# D1H.pdf register map
Vendor: Allwinner; Series: D1H.pdf; File version: 0.1
CPU: XuanTie C906 RISC-V CPU 0, little endian, MPU, FPU, double-precision FPU, 0 interrupt priority bits
Registers are 32-bit, read-write, reset 0x0 unless marked. A register's access mark holds for its fields unless they carry their own. Offsets are from the block's base; [hi:lo] are bit positions.

## CIR_TX
Base 0x02003000
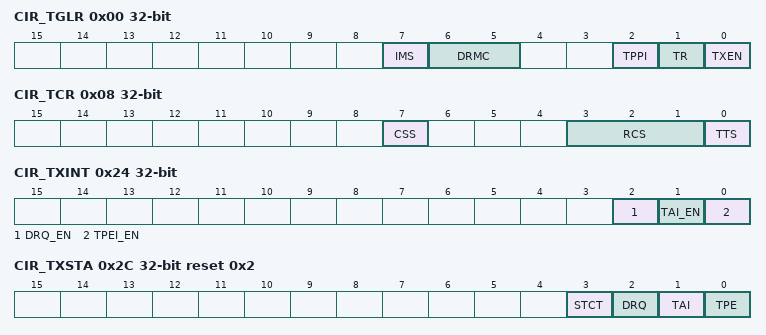
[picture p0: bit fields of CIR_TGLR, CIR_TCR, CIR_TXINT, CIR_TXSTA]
0x00 CIR_TGLR — CIR Transmit Global Register
  [7] IMS — Internal Modulation Select 0: The transmitting signal is not modulated 1: The transmitting signal is modulated internally
    0=not_modulated (The transmitting signal is not modulated); 1=modulated (The transmitting signal is modulated internally)
  [6:5] DRMC — Duty ratio of modulated carrier is high level/low level. 00: Low level is equal to high level 01: Low level is the double of high level 10: Low level is the triple of high level 11: Reserved
    0=equal (Low level is equal to high level); 1=the_double (Low level is the double of high level); 2=the_triple (Low level is the triple of high level)
  [2] TPPI — Transmit Pulse Polarity Invert 0: Not invert transmit pulse 1: Invert transmit pulse
    0=Not invert transmit pulse; 1=Invert transmit pulse
  [1] TR — Transmit Reset When this bit is set, the transmitting is reset. The FIFO will be flushed, the TIC filed and the CSS field will be cleared during Transmit Reset. This field will automatically be cleared when the Transmit Reset is finished, and the CIR transmitter will state Idle.
  [0] TXEN — Transmit Block Enable 0: Disable the CIR Transmitter 1: Enable the CIR Transmitter
    0=Disable the CIR Transmitter; 1=Enable the CIR Transmitter
0x04 CIR_TMCR reset 0x9E — CIR Transmit Modulation Control Register
  [7:0] RFMC — Reference Frequency of modulated carrier. Reference Frequency of modulated carrier based on a division of a fixed functional clock (FCLK). The range of the modulated carrier is usually 30 kHz to 60 kHz. Most consumer electronics is 38 kHz. The default modulated carrier is 38 kHz when FCLK is 12 MHz. RFMC= FCLK/((N+1)*(DRMC+2)).
0x08 CIR_TCR — CIR Transmit Control Register
  [7] CSS — Cyclical Pulse Start/Stop Control 0: Stop when cleared to '0'. From start to stop, all data in FIFO must be transmitted. 1: Start. Start to transmit when it is set to '1'.
    0=Stop when cleared to '0'. From start to stop, all data in FIFO must be transmitted.; 1=Start. Start to transmit when it is set to '1'.
  [3:1] RCS — Reference Clock Select for CIR Transmit The data in TX_FIFO is used to describe the pulse in Run-Length Code. The basic unit of pulse width is Reference Clock. 000: CIR Transmit reference clock is ir_clk 001: CIR Transmit reference clock is ir_clk/2 010: CIR Transmit reference clock is ir_clk/4 011: CIR Transmit reference clock is ir_clk/8 100: CIR Transmit reference clock is ir_clk/64 101: CIR Transmit reference clock is ir_clk/128 110: CIR Transmit reference clock is ir_clk/256 111: CIR Transmit reference clock is ir_clk/512
    0=ir_clk (CIR Transmit reference clock is ir_clk); 1=ir_clk_slash_2 (CIR Transmit reference clock is ir_clk/2); 2=ir_clk_slash_4 (CIR Transmit reference clock is ir_clk/4); 3=ir_clk_slash_8 (CIR Transmit reference clock is ir_clk/8); 4=ir_clk_slash_64 (CIR Transmit reference clock is ir_clk/64); 5=ir_clk_slash_128 (CIR Transmit reference clock is ir_clk/128); 6=ir_clk_slash_256 (CIR Transmit reference clock is ir_clk/256); 7=ir_clk_slash_512 (CIR Transmit reference clock is ir_clk/512)
  [0] TTS — Type of the transmission signal 0: The transmitting wave is a single non-cyclical pulse. 1: The transmitting wave is a cyclical short-pulse.
    0=a_single (The transmitting wave is a single non-cyclical pulse.); 1=a_cyclical (The transmitting wave is a cyclical short-pulse.)
0x0C CIR_IDC_H — CIR Transmit Idle Duration Threshold High Bit Register
  [3:0] IDC_H — Idle Duration Counter Threshold (High 4 bits) Idle Duration = 128*IDC*Ts (IDC = 0–4095) It is used in cyclical transmission mode. When all the data in FIFO is transmitted, the signals can be transmitted after a specific time.
0x10 CIR_IDC_L — CIR Transmit Idle Duration Threshold Low Bit Register
  [3:0] IDC_L — Idle Duration Counter Threshold (Low 8 bits) Idle Duration = 128*IDC*Ts (IDC = 0–4095) It is used in cyclical transmission mode. When all the data in FIFO is transmitted, the signals can be transmitted after a specific time.
0x14 CIR_TICR_H — CIR Transmit Idle Counter High Bit Register
  [7:0] TIC_H ro — Transmit Idle Counter_H (High 8 bits) It is used to count the idle duration of CIR transmitter by software. Count in 128*Ts (Sample Duration, 1/Fs) when the transmitter is idle, and it should be reset when the transmitter is active. When this counter reaches the maximum value (0xFFFF), it will stop automatically, and should not be cleared to zero.
0x18 CIR_TICR_L — CIR Transmit Idle Counter Low Bit Register
  [7:0] TIC_L ro — Transmit Idle Counter_L (Low 8 bits) It is used to count the idle duration of CIR transmitter by software. Count in 128*Ts (Sample Duration, 1/Fs) when the transmitter is idle, and it should be reset when the transmitter is active. When this counter reaches the maximum value (0xFFFF), it will stop automatically, and should not be cleared to zero.
0x20 CIR_TEL — CIR TX FIFO Empty Level Register
  [7:0] TEL — TX FIFO empty Level for DRQ and IRQ. TRIGGER_LEVEL = TEL + 1
0x24 CIR_TXINT — CIR Transmit Interrupt Control Register
  [2] DRQ_EN — TX FIFO DMA Enable 0: Disable 1: Enable When it is set to ‘1’, the TX FIFO DRQ is asserted if the number of the transmitting data in the FIFO is less than the RAL. The DRQ is de-asserted when the condition fails.
    0=Disable; 1=Enable When it is set to ‘1’, the TX FIFO DRQ is asserted if the number of the transmitting data in the FIFO is less than the RAL. The DRQ is de-asserted when the condition fails.
  [1] TAI_EN — TX FIFO Available Interrupt Enable 0: Disable 1: Enable
    0=Disable; 1=Enable
  [0] TPEI_EN — Transmit Packet End Interrupt Enable for Cyclical Pulse 0: Disable 1: Enable TUI_EN Transmitter FIFO Underrun Interrupt Enable for Non-cyclical Pulse 0: Disable 1: Enable
0x28 CIR_TAC reset 0x80 — CIR Transmit FIFO Available Counter Register
  [7:0] TAC ro — TX FIFO Available Space Counter 0x00: No available space in TX FIFO 0x01: 1 byte available space in TX FIFO 0x02: 2 bytes available space in TX FIFO … 0x80: 128 bytes available space in TX FIFO
    0=No available space in TX FIFO; 1=1 byte available space in TX FIFO; 2=2 bytes available space in TX FIFO …; 128=128 bytes available space in TX FIFO
0x2C CIR_TXSTA reset 0x2 — CIR Transmit Status Register
  [3] STCT ro — Status of CIR Transmitter 0: Idle 1: Active This bit will automatically set when the controller begins to transmit the data in the FIFO. The “1” will last when the data in the FIFO. It will automatically be cleared to “0” when all data in the FIFO is transmitted. The bit is for debugging. The output Level of Idle state is determined by the level of the last data output.
    0=Idle; 1=Active This bit will automatically set when the controller begins to transmit the data in the FIFO. The “1” will last when the data in the FIFO. It will automatically be cleared to “0” when all data in the FIFO is transmitted. The bit is for debugging. The output Level of Idle state is determined by the level of the last data output.
  [2] DRQ ro — DMA Request Flag When set to ‘1’, the TX FIFO DRQ is asserted if the number of the transmission data in the FIFO is less than the RAL. The DRQ is de- asserted when the condition fails. This bit is for debugging.
  [1] TAI — TX FIFO Available Interrupt Flag 0: TX FIFO not available by its level 1: TX FIFO available by its level Writing 1 clears this bit.
    0=TX_FIFO (TX FIFO not available by its level); 1=TX FIFO available by its level Writing 1 clears this bit
  [0] TPE — Transmitter Packet End Flag for Cyclical Pulse 0: Transmissions of address, control and data fields not completed 1: Transmissions of address, control and data fields completed TUR Transmitter FIFO Underrun Flag for Non-cyclical Pulse 0: No transmitter FIFO underrun 1: Transmitter FIFO underrun Writing 1 clears this bit.
0x30 CIR_TXT — CIR Transmit Threshold Register
  [7:0] NCTT — Non-cyclical Pulse Transmit Threshold The controller will trigger transmitting the data in the FIFO when the data byte number has reached the Transmit Threshold set in this field.
0x34 CIR_DMA_CTL reset 0xA5
  [7:0] DMA — Handshake Configuration 0xA5: DMA waiting cycle mode 0xEA: DMA handshake mode
    165=waiting_cycle (DMA waiting cycle mode); 234=handshake_mode (DMA handshake mode)
0x80 CIR_TXFIFO — CIR Transmit FIFO Data Register
  [7:0] TBF wo — Transmit Byte FIFO When the transmission is triggered, the data in the FIFO will be transmitted until the data number is transmitted completely. 10 Security System ..................................................................................................................................................... 1322 10.1 Crypto Engine ................................................................................................................................................ 1322 10.1.1 Overview ........................................................................................................................................... 1322 10.1.2 Block Diagram ................................................................................................................................... 1323 10.1.3 Functional Description ...................................................................................................................... 1323 10.1.4 Programming Guidelines ................................................................................................................... 1343 10.1.5 Register List ....................................................................................................................................... 1346 10.1.6 Register Description .......................................................................................................................... 1347 10.2 Security ID ..................................................................................................................................................... 1351 Figure 10-1 CE Block Diagram ......................................................................................................................................... 1323 Figure 10-2 DES Encryption and Decryption ................................................................................................................... 1324 Figure 10-3 3DES Encryption and Decryption of a 3-key Operation and a 2-key Operation .......................................... 1325 Figure 10-4 ECB Mode Encryption and Decryption......................................................................................................... 1326 Figure 10-5 CBC Mode Encryption and Decryption ........................................................................................................ 1327 Figure 10-6 CTR Mode Encryption and Decryption......................................................................................................... 1328 Figure 10-7 CFB Mode Encryption and Decryption ......................................................................................................... 1329 Figure 10-8 OFB Mode Encryption and Decryption ........................................................................................................ 1330 Figure 10-9 CTS Mode Encryption and Decryption ......................................................................................................... 1331 Figure 10-10 Structure of Task Descriptor Chaining ....................................................................................................... 1332 Figure 10-11 Word Address of Message ......................................................................................................................... 1339 Figure 10-12 Byte Order .................................................................................................................................................. 1339 Figure 10-13 Bit Order .................................................................................................................................................... 1339 Figure 10-14 The Storage Method of 32-bit IV ............................................................................................................... 1340 Figure 10-15 The Storage Method of 64-bit IV ............................................................................................................... 1340 Figure 10-16 Task Request Process ................................................................................................................................. 1343
